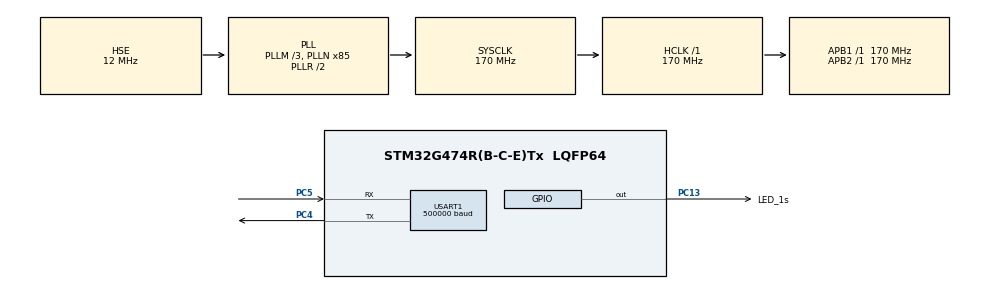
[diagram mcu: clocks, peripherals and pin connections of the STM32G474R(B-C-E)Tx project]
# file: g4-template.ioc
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Dma.Request0=USART1_RX
Dma.Request1=USART1_TX
Dma.USART1_RX.0.Direction=DMA_PERIPH_TO_MEMORY
Dma.USART1_RX.0.EventEnable=DISABLE
Dma.USART1_RX.0.Instance=DMA1_Channel1
Dma.USART1_RX.0.MemDataAlignment=DMA_MDATAALIGN_BYTE
Dma.USART1_RX.0.MemInc=DMA_MINC_ENABLE
Dma.USART1_RX.0.Mode=DMA_NORMAL
Dma.USART1_RX.0.PeriphDataAlignment=DMA_PDATAALIGN_BYTE
Dma.USART1_RX.0.PeriphInc=DMA_PINC_DISABLE
Dma.USART1_RX.0.Polarity=HAL_DMAMUX_REQ_GEN_RISING
Dma.USART1_RX.0.Priority=DMA_PRIORITY_VERY_HIGH
Dma.USART1_RX.0.RequestNumber=1
Dma.USART1_RX.0.SignalID=NONE
Dma.USART1_RX.0.SyncEnable=DISABLE
Dma.USART1_RX.0.SyncPolarity=HAL_DMAMUX_SYNC_NO_EVENT
Dma.USART1_RX.0.SyncRequestNumber=1
Dma.USART1_RX.0.SyncSignalID=NONE
Dma.USART1_TX.1.Direction=DMA_MEMORY_TO_PERIPH
Dma.USART1_TX.1.EventEnable=DISABLE
Dma.USART1_TX.1.Instance=DMA1_Channel2
Dma.USART1_TX.1.MemDataAlignment=DMA_MDATAALIGN_BYTE
Dma.USART1_TX.1.MemInc=DMA_MINC_ENABLE
Dma.USART1_TX.1.Mode=DMA_NORMAL
Dma.USART1_TX.1.PeriphDataAlignment=DMA_PDATAALIGN_BYTE
Dma.USART1_TX.1.PeriphInc=DMA_PINC_DISABLE
Dma.USART1_TX.1.Polarity=HAL_DMAMUX_REQ_GEN_RISING
Dma.USART1_TX.1.Priority=DMA_PRIORITY_VERY_HIGH
Dma.USART1_TX.1.RequestNumber=1
Dma.USART1_TX.1.SignalID=NONE
Dma.USART1_TX.1.SyncEnable=DISABLE
Dma.USART1_TX.1.SyncPolarity=HAL_DMAMUX_SYNC_NO_EVENT
Dma.USART1_TX.1.SyncRequestNumber=1
Dma.USART1_TX.1.SyncSignalID=NONE
Mcu.Family=STM32G4
Mcu.Name=STM32G474R(B-C-E)Tx
Mcu.Package=LQFP64
NVIC.DMA1_Channel1_IRQn=true\:0\:0\:false\:false\:true\:false\:true\:true
NVIC.DMA1_Channel2_IRQn=true\:0\:0\:false\:false\:true\:false\:true\:true
NVIC.PriorityGroup=NVIC_PRIORITYGROUP_4
NVIC.TIM1_UP_TIM16_IRQn=true\:1\:0\:true\:false\:true\:true\:true\:true
NVIC.USART1_IRQn=true\:0\:0\:false\:false\:true\:true\:true\:true
PA13.Mode=Serial_Wire
PA13.Signal=SYS_JTMS-SWDIO
PA14.Mode=Serial_Wire
PA14.Signal=SYS_JTCK-SWCLK
PC13.GPIO_Label=LED_1s
PC13.Signal=GPIO_Output
PC4.GPIO_Speed=GPIO_SPEED_FREQ_VERY_HIGH
PC4.Mode=Asynchronous
PC4.Signal=USART1_TX
PC5.GPIO_Speed=GPIO_SPEED_FREQ_VERY_HIGH
PC5.Mode=Asynchronous
PC5.Signal=USART1_RX
PF0-OSC_IN.Mode=HSE-External-Oscillator
PF0-OSC_IN.Signal=RCC_OSC_IN
PF1-OSC_OUT.Mode=HSE-External-Oscillator
PF1-OSC_OUT.Signal=RCC_OSC_OUT
ProjectManager.HeapSize=0x200
ProjectManager.StackSize=0x400
ProjectManager.TargetToolchain=STM32CubeIDE
RCC.ADC12Freq_Value=170000000
RCC.ADC345Freq_Value=170000000
RCC.AHBFreq_Value=170000000
RCC.APB1Freq_Value=170000000
RCC.APB1TimFreq_Value=170000000
RCC.APB2Freq_Value=170000000
RCC.APB2TimFreq_Value=170000000
RCC.CortexFreq_Value=170000000
RCC.EXTERNAL_CLOCK_VALUE=12288000
RCC.HCLKFreq_Value=170000000
RCC.HSE_VALUE=12000000
RCC.HSI48_VALUE=48000000
RCC.HSI_VALUE=16000000
RCC.LSE_VALUE=32768
RCC.PLLM=RCC_PLLM_DIV3
RCC.PLLN=85
RCC.PLLSourceVirtual=RCC_PLLSOURCE_HSE
RCC.SYSCLKFreq_VALUE=170000000
RCC.SYSCLKSource=RCC_SYSCLKSOURCE_PLLCLK
RCC.USBFreq_Value=170000000
RCC.VCOOutputFreq_Value=340000000
TIM1.AutoReloadPreload=TIM_AUTORELOAD_PRELOAD_ENABLE
TIM1.Channel-PWM\ Generation1\ No\ Output=TIM_CHANNEL_1
TIM1.PeriodNoDither=99
TIM1.Prescaler=169
USART1.BaudRate=500000
USART1.DMADisableonRxErrorParam=ADVFEATURE_DMA_ENABLEONRXERROR
USART1.OverrunDisableParam=ADVFEATURE_OVERRUN_ENABLE
USART1.Parity=PARITY_EVEN
USART1.SwapParam=ADVFEATURE_SWAP_ENABLE
USART1.VirtualMode-Asynchronous=VM_ASYNC
USART1.WordLength=WORDLENGTH_9B
VP_SYS_VS_DBSignals.Mode=DisableDeadBatterySignals
VP_TIM1_VS_no_output1.Mode=PWM Generation1 No Output
board=custom

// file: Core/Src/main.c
/* USER CODE BEGIN Header */
/**
  ******************************************************************************
  * @file           : main.c
  * @brief          : Main program body
  ******************************************************************************
  * @attention
  *
  * Copyright (c) 2025 STMicroelectronics.
  * All rights reserved.
  *
  * This software is licensed under terms that can be found in the LICENSE file
  * in the root directory of this software component.
  * If no LICENSE file comes with this software, it is provided AS-IS.
  *
  ******************************************************************************
  */
/* USER CODE END Header */
#include "main.h"

/* USER CODE BEGIN Includes */
#include "appl_main.h"

/* USER CODE END Includes */

TIM_HandleTypeDef htim1;

UART_HandleTypeDef huart1;
DMA_HandleTypeDef hdma_usart1_rx;
DMA_HandleTypeDef hdma_usart1_tx;

void SystemClock_Config(void);
static void MX_GPIO_Init(void);
static void MX_DMA_Init(void);
static void MX_USART1_UART_Init(void);
static void MX_TIM1_Init(void);

int main(void)
{

  /* MCU Configuration--------------------------------------------------------*/

  /* Reset of all peripherals, Initializes the Flash interface and the Systick. */
  HAL_Init();

  /* Configure the system clock */
  SystemClock_Config();

  /* Initialize all configured peripherals */
  MX_GPIO_Init();
  MX_DMA_Init();
  MX_USART1_UART_Init();
  MX_TIM1_Init();
  /* USER CODE BEGIN 2 */
  custom_init();
  /* USER CODE END 2 */

  /* Infinite loop */
  /* USER CODE BEGIN WHILE */
  while (1)
  {
    main_loop();
    /* USER CODE END WHILE */

  }
}

void SystemClock_Config(void)
{
  RCC_OscInitTypeDef RCC_OscInitStruct = {0};
  RCC_ClkInitTypeDef RCC_ClkInitStruct = {0};

  /** Configure the main internal regulator output voltage
  */
  HAL_PWREx_ControlVoltageScaling(PWR_REGULATOR_VOLTAGE_SCALE1_BOOST);

  /** Initializes the RCC Oscillators according to the specified parameters
  * in the RCC_OscInitTypeDef structure.
  */
  RCC_OscInitStruct.OscillatorType = RCC_OSCILLATORTYPE_HSE;
  RCC_OscInitStruct.HSEState = RCC_HSE_ON;
  RCC_OscInitStruct.PLL.PLLState = RCC_PLL_ON;
  RCC_OscInitStruct.PLL.PLLSource = RCC_PLLSOURCE_HSE;
  RCC_OscInitStruct.PLL.PLLM = RCC_PLLM_DIV3;
  RCC_OscInitStruct.PLL.PLLN = 85;
  RCC_OscInitStruct.PLL.PLLP = RCC_PLLP_DIV2;
  RCC_OscInitStruct.PLL.PLLQ = RCC_PLLQ_DIV2;
  RCC_OscInitStruct.PLL.PLLR = RCC_PLLR_DIV2;
  if (HAL_RCC_OscConfig(&RCC_OscInitStruct) != HAL_OK)
  {
    Error_Handler();
  }

  /** Initializes the CPU, AHB and APB buses clocks
  */
  RCC_ClkInitStruct.ClockType = RCC_CLOCKTYPE_HCLK|RCC_CLOCKTYPE_SYSCLK
                              |RCC_CLOCKTYPE_PCLK1|RCC_CLOCKTYPE_PCLK2;
  RCC_ClkInitStruct.SYSCLKSource = RCC_SYSCLKSOURCE_PLLCLK;
  RCC_ClkInitStruct.AHBCLKDivider = RCC_SYSCLK_DIV1;
  RCC_ClkInitStruct.APB1CLKDivider = RCC_HCLK_DIV1;
  RCC_ClkInitStruct.APB2CLKDivider = RCC_HCLK_DIV1;

  if (HAL_RCC_ClockConfig(&RCC_ClkInitStruct, FLASH_LATENCY_4) != HAL_OK)
  {
    Error_Handler();
  }
}

static void MX_TIM1_Init(void)
{

  TIM_MasterConfigTypeDef sMasterConfig = {0};
  TIM_OC_InitTypeDef sConfigOC = {0};
  TIM_BreakDeadTimeConfigTypeDef sBreakDeadTimeConfig = {0};

  htim1.Instance = TIM1;
  htim1.Init.Prescaler = 169;
  htim1.Init.CounterMode = TIM_COUNTERMODE_UP;
  htim1.Init.Period = 99;
  htim1.Init.ClockDivision = TIM_CLOCKDIVISION_DIV1;
  htim1.Init.RepetitionCounter = 0;
  htim1.Init.AutoReloadPreload = TIM_AUTORELOAD_PRELOAD_ENABLE;
  if (HAL_TIM_PWM_Init(&htim1) != HAL_OK)
  {
    Error_Handler();
  }
  sMasterConfig.MasterOutputTrigger = TIM_TRGO_RESET;
  sMasterConfig.MasterOutputTrigger2 = TIM_TRGO2_RESET;
  sMasterConfig.MasterSlaveMode = TIM_MASTERSLAVEMODE_DISABLE;
  if (HAL_TIMEx_MasterConfigSynchronization(&htim1, &sMasterConfig) != HAL_OK)
  {
    Error_Handler();
  }
  sConfigOC.OCMode = TIM_OCMODE_PWM1;
  sConfigOC.Pulse = 0;
  sConfigOC.OCPolarity = TIM_OCPOLARITY_HIGH;
  sConfigOC.OCNPolarity = TIM_OCNPOLARITY_HIGH;
  sConfigOC.OCFastMode = TIM_OCFAST_DISABLE;
  sConfigOC.OCIdleState = TIM_OCIDLESTATE_RESET;
  sConfigOC.OCNIdleState = TIM_OCNIDLESTATE_RESET;
  if (HAL_TIM_PWM_ConfigChannel(&htim1, &sConfigOC, TIM_CHANNEL_1) != HAL_OK)
  {
    Error_Handler();
  }
  sBreakDeadTimeConfig.OffStateRunMode = TIM_OSSR_DISABLE;
  sBreakDeadTimeConfig.OffStateIDLEMode = TIM_OSSI_DISABLE;
  sBreakDeadTimeConfig.LockLevel = TIM_LOCKLEVEL_OFF;
  sBreakDeadTimeConfig.DeadTime = 0;
  sBreakDeadTimeConfig.BreakState = TIM_BREAK_DISABLE;
  sBreakDeadTimeConfig.BreakPolarity = TIM_BREAKPOLARITY_HIGH;
  sBreakDeadTimeConfig.BreakFilter = 0;
  sBreakDeadTimeConfig.BreakAFMode = TIM_BREAK_AFMODE_INPUT;
  sBreakDeadTimeConfig.Break2State = TIM_BREAK2_DISABLE;
  sBreakDeadTimeConfig.Break2Polarity = TIM_BREAK2POLARITY_HIGH;
  sBreakDeadTimeConfig.Break2Filter = 0;
  sBreakDeadTimeConfig.Break2AFMode = TIM_BREAK_AFMODE_INPUT;
  sBreakDeadTimeConfig.AutomaticOutput = TIM_AUTOMATICOUTPUT_DISABLE;
  if (HAL_TIMEx_ConfigBreakDeadTime(&htim1, &sBreakDeadTimeConfig) != HAL_OK)
  {
    Error_Handler();
  }

}

static void MX_USART1_UART_Init(void)
{

  huart1.Instance = USART1;
  huart1.Init.BaudRate = 500000;
  huart1.Init.WordLength = UART_WORDLENGTH_9B;
  huart1.Init.StopBits = UART_STOPBITS_1;
  huart1.Init.Parity = UART_PARITY_EVEN;
  huart1.Init.Mode = UART_MODE_TX_RX;
  huart1.Init.HwFlowCtl = UART_HWCONTROL_NONE;
  huart1.Init.OverSampling = UART_OVERSAMPLING_16;
  huart1.Init.OneBitSampling = UART_ONE_BIT_SAMPLE_DISABLE;
  huart1.Init.ClockPrescaler = UART_PRESCALER_DIV1;
  huart1.AdvancedInit.AdvFeatureInit = UART_ADVFEATURE_SWAP_INIT;
  huart1.AdvancedInit.Swap = UART_ADVFEATURE_SWAP_ENABLE;
  if (HAL_UART_Init(&huart1) != HAL_OK)
  {
    Error_Handler();
  }
  if (HAL_UARTEx_SetTxFifoThreshold(&huart1, UART_TXFIFO_THRESHOLD_1_8) != HAL_OK)
  {
    Error_Handler();
  }
  if (HAL_UARTEx_SetRxFifoThreshold(&huart1, UART_RXFIFO_THRESHOLD_1_8) != HAL_OK)
  {
    Error_Handler();
  }
  if (HAL_UARTEx_DisableFifoMode(&huart1) != HAL_OK)
  {
    Error_Handler();
  }

}

static void MX_DMA_Init(void)
{

  /* DMA controller clock enable */
  __HAL_RCC_DMAMUX1_CLK_ENABLE();
  __HAL_RCC_DMA1_CLK_ENABLE();

  /* DMA interrupt init */
  /* DMA1_Channel1_IRQn interrupt configuration */
  HAL_NVIC_SetPriority(DMA1_Channel1_IRQn, 0, 0);
  HAL_NVIC_EnableIRQ(DMA1_Channel1_IRQn);
  /* DMA1_Channel2_IRQn interrupt configuration */
  HAL_NVIC_SetPriority(DMA1_Channel2_IRQn, 0, 0);
  HAL_NVIC_EnableIRQ(DMA1_Channel2_IRQn);

}

static void MX_GPIO_Init(void)
{
  GPIO_InitTypeDef GPIO_InitStruct = {0};

  /* GPIO Ports Clock Enable */
  __HAL_RCC_GPIOC_CLK_ENABLE();
  __HAL_RCC_GPIOF_CLK_ENABLE();
  __HAL_RCC_GPIOA_CLK_ENABLE();

  /*Configure GPIO pin Output Level */
  HAL_GPIO_WritePin(LED_1s_GPIO_Port, LED_1s_Pin, GPIO_PIN_RESET);

  /*Configure GPIO pin : LED_1s_Pin */
  GPIO_InitStruct.Pin = LED_1s_Pin;
  GPIO_InitStruct.Mode = GPIO_MODE_OUTPUT_PP;
  GPIO_InitStruct.Pull = GPIO_NOPULL;
  GPIO_InitStruct.Speed = GPIO_SPEED_FREQ_LOW;
  HAL_GPIO_Init(LED_1s_GPIO_Port, &GPIO_InitStruct);

}

void Error_Handler(void)
{
  __disable_irq();
  while (1)
  {
  }
}
